# NUC400_v1 register map
File version: 1.0
Registers are 32-bit, read-write, reset 0x0 unless marked. A register's access mark holds for its fields unless they carry their own. Offsets are from the block's base; [hi:lo] are bit positions; {n}, {i} and the like mark numbered series.

## FMC — FMC Register Map
Base 0x4000C000
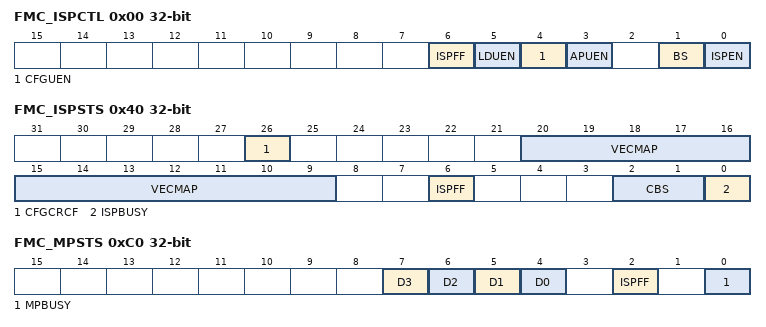
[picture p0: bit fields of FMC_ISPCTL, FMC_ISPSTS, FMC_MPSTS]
0x00 FMC_ISPCTL — ISP Control Register
  [6] ISPFF — ISP Fail Flag (Write Protect). This bit is set by hardware when a triggered ISP meets any of the following conditions: (1) APROM writes to itself if APUEN is set to 0. (2) LDROM writes to itself if LDUEN is set to 0. (3) CONFIG is erased/programmed if CFGUEN is set to 0. (4) Destination address is illegal, such as over an available range. Note: This bit needs to be cleared by writing 1 to it.
  [5] LDUEN — LDROM Update Enable Bit (Write Protect). LDROM update enable bit.
    0=LDROM cannot be updated; 1=LDROM can be updated
  [4] CFGUEN — Config-Bits Update By ISP Enable Bit (Write Protect)
    0=ISP Disabled to update config-bits; 1=ISP Enabled to update config-bits
  [3] APUEN — APROM Update Enable Bit (Write Protect)
    0=APROM cannot be updated when the chip runs in APROM; 1=APROM can be updated when the chip runs in APROM
  [1] BS — Boot Select (Write Protect). Set/clear this bit to select next booting from LDROM/APROM, respectively. This bit also functions as chip booting status flag, which can be used to check where chip booted from. This bit is initiated with the inversed value of CBS in Config0 after any reset is happened except CPU reset (RSTS_CPU is 1) or system reset (RSTS_SYS) is happened
    0=Boot from APROM; 1=Boot from LDROM
  [0] ISPEN — ISP Enable Bit (Write Protect). ISP function enable bit. Set this bit to enable ISP function.
    0=ISP function Disabled; 1=ISP function Enabled
0x04 FMC_ISPADDR — ISP Address Register
  [31:0] ISPADDR — ISP Address. The NUC442/NUC472 series is equipped with an embedded flash and supports word program only. ISPADDR[1:0] must be kept 00b for ISP operation.
0x08 FMC_ISPDAT — ISP Data Register
  [31:0] ISPDAT — ISP Data. Write data to this register before ISP program operation. Read data from this register after ISP read operation.
0x0C FMC_ISPCMD — ISP Command Register
  [5:0] CMD — ISP Command. Please check the table below for ISP commands.
0x10 FMC_ISPTRG — ISP Trigger Register
  [0] ISPGO — ISP Start Trigger. Write 1 to start ISP operation and this bit will be cleared to 0 by hardware automatically when ISP operation is finished. This bit is the protected bit, It means programming this bit needs to write "59h", "16h", "88h" to address 0x4000_0100 to disable register protection. Refer to the register SYS_REGLCTL at address GCR_BA+0x100
    0=ISP operation is finished; 1=ISP is progressed
0x14 FMC_DFBA ro reset not defined — Data Flash Base Address
  [31:0] DFBA — Data Flash Base Address. This register indicates data flash start address. It is a read only register. The data flash is shared with APROM and data flash size is defined by user configuration and the content of this register is loaded from Config1.
0x18 FMC_FTCTL — Flash Access Time Control Register
  [6:4] FOM — Frequency Optimization Mode (Write Protect)
0x40 FMC_ISPSTS ro — ISP Status Register
  [26] CFGCRCF — User-Configuration CRC Check Flag (Read Only). This bit is set by hardware when detecting CONFIG CRC checksum is error
    0=CONFIG CRC checksum is OK; 1=CONFIG CRC checksum error and force chip into LOCK mode
  [20:9] VECMAP — Vector Page Mapping Address (Read Only). The current flash address space 0x0000_0000~0x0000_07FF is mapping to address {VECMAP[11:2], 11'h000} ~ {VECMAP[11:2], 11'h7FF} VECMAP[1:0] is needed to set 0.
  [6] ISPFF — ISP Fail Flag (Read Only). This bit is set by hardware when a triggered ISP meets any of the following conditions: (1) APROM writes to itself if APUEN is set to 0. (2) LDROM writes to itself if LDUEN is set to 0. (3) CONFIG is erased/programmed if CFGUEN is set to 0. (4) Destination address is illegal, such as over an available range.
  [2:1] CBS — Chip Boot Selection Mode This CBS field is just a copy of User-Configuration Config0 CBS[7:6].
  [0] ISPBUSY — ISP Busy Flag
    0=ISP operation is finished; 1=ISP is progressed
0x80 FMC_MPDAT0 — ISP Multi-word Program Data0 Register
  [31:0] ISPDAT0 — ISP Data 0. This register is the first 32-bit data for 32b/64b/multi-word program, and it is also the mirror of FMC_ISPDAT register, both registers keep the same data.
0x84 FMC_MPDAT1 — ISP Multi-word Program Data1 Register
  [31:0] ISPDAT1 — ISP Data 1. This register is the second 32-bit data for 32b/64b/multi-word program.
0x88 FMC_MPDAT2 — ISP Multi-word Program Data2 Register
  [31:0] ISPDAT2 — ISP Data 2. This register is the third 32-bit data for 32b/64b/multi-word program.
0x8C FMC_MPDAT3 — ISP Multi-word Program Data3 Register
  [31:0] ISPDAT3 — ISP Data 3. This register is the fourth 32-bit data for 32b/64b/multi-word program.
0xC0 FMC_MPSTS ro — ISP Multi-word Program Status Register
  [7] D3 — ISP DATA 3 Flag (Read Only). This bit is set when FMC_MPDAT3 is written and auto-clear to 0 when the FMC_MPDAT3 is programmed to flash complete.
    0=FMC_MPDAT3 register is empty, or program to flash complete; 1=FMC_MPDAT3 register has been written, and not programmed to flash yet
  [6] D2 — ISP DATA 2 Flag (Read Only). This bit is set when FMC_MPDAT2 is written and auto-clear to 0 when the FMC_MPDAT2 is programmed to flash complete.
    0=FMC_MPDAT2 register is empty, or program to flash complete; 1=FMC_MPDAT2 register has been written, and not programmed to flash yet
  [5] D1 — ISP DATA 1 Flag (Read Only). This bit is set when FMC_MPDAT1 is written and auto-clear to 0 when the FMC_MPDAT1 is programmed to flash complete.
    0=FMC_MPDAT1 register is empty, or program to flash complete; 1=FMC_MPDAT1 register has been written, and not programmed to flash yet
  [4] D0 — ISP DATA 0 Flag (Read Only). This bit is set when FMC_MPDAT0 is written and auto-clear to 0 when the FMC_MPDAT0 is programmed to flash complete.
    0=FMC_MPDAT0 register is empty, or program to flash complete; 1=FMC_ISPDAT0 register has been written, and not programmed to flash yet
  [2] ISPFF — ISP Fail Flag (Read Only). This bit is set when ISP Multi-Word Program operation failed.
  [0] MPBUSY — ISP Multi-Word Program Busy Flag (Read Only)
    0=ISP Multi-Word Program operation is aborted or finished; 1=ISP Multi-Word Program operation is progressed
0xC4 FMC_MPADDR ro — ISP Multi-word Program Address Status Register
  [31:0] MPADDR — ISP Multi-Word Program Address Status. MPADDR is the address of ISP Multi-Word Program operation when MPBUSY flag is 1. MPADDR will keep the final address when Multi-Word Program is aborted or finished.
